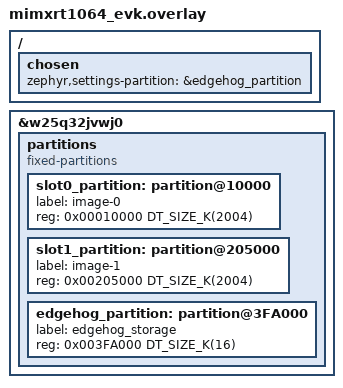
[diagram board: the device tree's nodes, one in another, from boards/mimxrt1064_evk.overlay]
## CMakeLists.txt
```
# (C) Copyright 2024, SECO Mind Srl
#
# SPDX-License-Identifier: Apache-2.0

function(concat_if_exists FILE_PATH STRING_NAME)
    # Check if the file exists
    file(GLOB FILE_TO_ADD ${FILE_PATH})

    # If the file exists, add it to the list
    if(EXISTS ${FILE_TO_ADD})
        set(${STRING_NAME} "${${STRING_NAME}};${FILE_PATH}" PARENT_SCOPE)
    endif()
endfunction()

cmake_minimum_required(VERSION 3.20.0)

# add private configuration for common modules before declaring the zephyr project
concat_if_exists(${CMAKE_CURRENT_LIST_DIR}/private.conf EXTRA_CONF_FILE)
# add per board cmake configuration
include(${CMAKE_CURRENT_LIST_DIR}/boards/${BOARD}.cmake OPTIONAL)

find_package(Zephyr REQUIRED HINTS $ENV{ZEPHYR_BASE})
project(simple)

FILE(GLOB app_sources src/*.c)

if(NOT CONFIG_WIFI)
    LIST(REMOVE_ITEM app_sources ${CMAKE_CURRENT_LIST_DIR}/src/wifi.c)
endif()

# Verify that this sample is built through sysbuild to ensure MCUboot is
# automatically included and that sample specific MCUboot configurations are
# used when building MCUboot.
test_sysbuild()

target_include_directories(app PRIVATE src/include)
target_sources(app PRIVATE ${app_sources})
```

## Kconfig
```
# (C) Copyright 2024, SECO Mind Srl
#
# SPDX-License-Identifier: Apache-2.0
#
# This file is the application Kconfig entry point. All application Kconfig
# options can be defined here or included via other application Kconfig files.
# You can browse these options using the west targets menuconfig (terminal) or
# guiconfig (GUI).

menu "Zephyr"
source "Kconfig.zephyr"
endmenu

rsource "../../Kconfig"

menu "Sample application"
    config CREDENTIAL_SECRET
        string "Astarte credential secret"
        default ""
        help
            The credential secret to be used to connect to Astarte.
            
config WIFI_SSID
    string "WiFi SSID"
    default "myssid"
    help
        SSID (network name) for the example to connect to.

config WIFI_PASSWORD
    string "WiFi Password"
    default "mypassword"
    help
        WiFi password (WPA or WPA2) for the example to use.
endmenu

module = APP
module-str = APP
source "subsys/logging/Kconfig.template.log_config"
```

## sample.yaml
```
# (C) Copyright 2024, SECO Mind Srl
#
# SPDX-License-Identifier: Apache-2.0
# This file is provided so that the application can be compiled using Twister,
# the Zephyr testing tool. In this file, multiple combinations can be specified,
# so that you can easily test all of them locally or in CI.
sample:
  description: Simple sample for using the library
  name: simple-sample
tests:
  simple.default:
    build_only: true
    integration_platforms:
      - mimxrt1064_evk
      - native_sim
```

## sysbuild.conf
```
# (C) Copyright 2024, SECO Mind Srl
#
# SPDX-License-Identifier: Apache-2.0

SB_CONFIG_BOOTLOADER_MCUBOOT=y
```

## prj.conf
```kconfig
# (C) Copyright 2024, SECO Mind Srl
#
# SPDX-License-Identifier: Apache-2.0
#
# This is a Kconfig fragment which can be used to enable debug-related options
# in the application. See the README for more details.

# logging
CONFIG_LOG=y
CONFIG_CBPRINTF_FP_SUPPORT=y

# compiler
CONFIG_DEBUG_OPTIMIZATIONS=y

# console
CONFIG_CONSOLE=y

# UART console
CONFIG_SERIAL=y
CONFIG_UART_CONSOLE=y

# Increased stack size
CONFIG_MAIN_STACK_SIZE=65536

# MQTT options
CONFIG_MQTT_KEEPALIVE=60

# DNS resolver
CONFIG_DNS_RESOLVER=y
CONFIG_DNS_RESOLVER_AI_MAX_ENTRIES=4
CONFIG_DNS_SERVER_IP_ADDRESSES=y
CONFIG_DNS_SERVER1="8.8.8.8" # Google DNS

# MbedTLS
CONFIG_MBEDTLS=y
CONFIG_MBEDTLS_BUILTIN=y
CONFIG_MBEDTLS_ENABLE_HEAP=y
# 55kB is the max absolute value, could be set much lower
CONFIG_MBEDTLS_HEAP_SIZE=55000
# 16384 is the max absolute value, could be set much lower
CONFIG_MBEDTLS_SSL_MAX_CONTENT_LEN=16384
CONFIG_MBEDTLS_PEM_CERTIFICATE_FORMAT=y # Does not include writing
CONFIG_MBEDTLS_PK_WRITE_C=y # Required for PEM writing (also needs MBEDTLS_PEM_WRITE_C)
CONFIG_MBEDTLS_ENTROPY_ENABLED=y
CONFIG_MBEDTLS_ZEPHYR_ENTROPY=y
CONFIG_MBEDTLS_USER_CONFIG_ENABLE=y
CONFIG_MBEDTLS_USER_CONFIG_FILE="../../astarte-device-sdk-zephyr/samples/common/include/tls-conf.h"
CONFIG_MBEDTLS_TLS_VERSION_1_2=y
CONFIG_MBEDTLS_CIPHER=y
CONFIG_MBEDTLS_CIPHER_ALL_ENABLED=y
CONFIG_MBEDTLS_SERVER_NAME_INDICATION=y
CONFIG_MBEDTLS_KEY_EXCHANGE_ALL_ENABLED=y
CONFIG_MBEDTLS_HASH_ALL_ENABLED=y
CONFIG_MBEDTLS_CTR_DRBG_ENABLED=y
CONFIG_MBEDTLS_HMAC_DRBG_ENABLED=y
CONFIG_MBEDTLS_CHACHAPOLY_AEAD_ENABLED=y
CONFIG_MBEDTLS_ECDH_C=y
CONFIG_MBEDTLS_ECDSA_C=y
CONFIG_MBEDTLS_ECJPAKE_C=y
CONFIG_MBEDTLS_ECP_C=y
CONFIG_MBEDTLS_ECP_ALL_ENABLED=y
CONFIG_MBEDTLS_GENPRIME_ENABLED=y
CONFIG_MBEDTLS_PKCS5_C=y
CONFIG_MBEDTLS_X509_CRL_PARSE_C=y
CONFIG_MBEDTLS_X509_CSR_PARSE_C=y
CONFIG_MBEDTLS_X509_CSR_WRITE_C=y

# Enable entropy generator
CONFIG_ENTROPY_GENERATOR=y

# Enable Network management info
CONFIG_NET_MGMT_EVENT_INFO=y

# Sockets
CONFIG_NET_SOCKETS=y
CONFIG_NET_SOCKETS_POLL_MAX=4
CONFIG_NET_SOCKETS_SOCKOPT_TLS=y

# Use DHCP for IPv4 and IPv6
CONFIG_NET_DHCPV4=y
CONFIG_NET_DHCPV6=y

# Generic networking options
CONFIG_NET_TX_STACK_SIZE=2048
CONFIG_NET_RX_STACK_SIZE=2048
CONFIG_NET_PKT_RX_COUNT=10
CONFIG_NET_PKT_TX_COUNT=10
CONFIG_NET_BUF_RX_COUNT=40
CONFIG_NET_BUF_TX_COUNT=40
CONFIG_NET_MAX_CONTEXTS=10
CONFIG_NET_MGMT=y
CONFIG_NET_MGMT_EVENT=y
CONFIG_NET_IPV4=y
CONFIG_NET_IPV6=y
CONFIG_NET_TCP=y

# Astarte device SDK
CONFIG_ASTARTE_DEVICE_SDK=y
CONFIG_ASTARTE_DEVICE_SDK_HOSTNAME="."
# The two certificate tags are the same as the root CA is the same for Astarte API and MQTT broker.
CONFIG_ASTARTE_DEVICE_SDK_HTTPS_CA_CERT_TAG=1
CONFIG_ASTARTE_DEVICE_SDK_MQTTS_CA_CERT_TAG=1
CONFIG_ASTARTE_DEVICE_SDK_CLIENT_CERT_TAG=2
CONFIG_ASTARTE_DEVICE_SDK_PAIRING_JWT=""
CONFIG_ASTARTE_DEVICE_SDK_REALM_NAME="."
CONFIG_ASTARTE_DEVICE_SDK_PERMANENT_STORAGE=n

# Configure the name of the binary
# This will also be used to identify the edgehog image
CONFIG_KERNEL_BIN_NAME="simple-sample"

# Edgehog device
CONFIG_EDGEHOG_DEVICE=y
CONFIG_EDGEHOG_DEVICE_CA_CERT_OTA_TAG=3

# System info interface data
CONFIG_EDGEHOG_DEVICE_PART_NUMBER=""
CONFIG_EDGEHOG_DEVICE_SERIAL_NUMBER=""

# WiFi credentials
CONFIG_WIFI_SSID="."
CONFIG_WIFI_PASSWORD="."

# Sample configuration
CONFIG_CREDENTIAL_SECRET="."
CONFIG_DEVICE_ID="......................"

CONFIG_NET_SOCKETS_TLS_MAX_CONTEXTS=4

# EDGEHOG_DEVICE_ZBUS_OTA_EVENT
# Enabling these options if you have enabled the EDGEHOG_DEVICE_ZBUS_OTA_EVENT.
# CONFIG_MAIN_THREAD_PRIORITY=5
# CONFIG_ZBUS_LOG_LEVEL_INF=y

CONFIG_THREAD_MONITOR=y
CONFIG_INIT_STACKS=y
CONFIG_THREAD_STACK_INFO=y

CONFIG_POSIX_TIMERS=y
CONFIG_SNTP=y
CONFIG_POSIX_CLOCK=y # deprecated but needed for the config below
CONFIG_NET_CONFIG_CLOCK_SNTP_INIT=y
CONFIG_NET_CONFIG_SNTP_INIT_SERVER="0.pool.ntp.org"
CONFIG_NET_CONFIG_SNTP_INIT_TIMEOUT=3000

CONFIG_SETTINGS=y

# Enable base64 encoding and decoding
CONFIG_BASE64=y

# Enable system hashmaps
CONFIG_SYS_HASH_MAP=y
CONFIG_SYS_HASH_FUNC32=y

# Enable JSON library
CONFIG_JSON_LIBRARY=y

# Enable networking
CONFIG_NETWORKING=y

# Enable HTTP client
CONFIG_HTTP_CLIENT=y

# MQTT options
CONFIG_MQTT_LIB=y
CONFIG_MQTT_LIB_TLS=y
CONFIG_MQTT_CLEAN_SESSION=y
CONFIG_MQTT_KEEPALIVE=60

# Enable flash
CONFIG_FLASH=y
CONFIG_FLASH_MAP=y
CONFIG_FLASH_PAGE_LAYOUT=y

# Enable NVS
CONFIG_NVS=y
# CONFIG_NVS_LOG_LEVEL_WRN=y

# Edgehog depends on
CONFIG_IMG_MANAGER=y
CONFIG_STREAM_FLASH=y
CONFIG_REBOOT=y

# CONFIG_ZVFS_OPEN_MAX=16
```

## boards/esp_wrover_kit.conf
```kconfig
# (C) Copyright 2024, SECO Mind Srl
#
# SPDX-License-Identifier: Apache-2.0

# Enable wifi drivers
CONFIG_WIFI=y
CONFIG_WIFI_ESP32=y

# Added to prevent error with missing #include <ethernet/eth_stats.h> for esp_wifi_drv.c
# Adding this line will cause CMAKE Warning: No SOURCES given to Zephyr library: drivers__ethernet
# Just ignore.
CONFIG_NET_L2_ETHERNET=y

CONFIG_NET_CONFIG_SETTINGS=y

# Enable ESP32 External RAM
CONFIG_ESP_SPIRAM=y
CONFIG_ESP32_WIFI_NET_ALLOC_SPIRAM=y
CONFIG_MBEDTLS_ENABLE_HEAP=n

# EDGEHOG_DEVICE_ZBUS_OTA_EVENT 
# Enabling these options if you have enabled the EDGEHOG_DEVICE_ZBUS_OTA_EVENT.
# CONFIG_LOG_MODE_MINIMAL=y
```

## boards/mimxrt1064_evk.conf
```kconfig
# (C) Copyright 2024, SECO Mind Srl
#
# SPDX-License-Identifier: Apache-2.0

# Ethernet settings
CONFIG_NET_L2_ETHERNET=y
CONFIG_NET_L2_ETHERNET_MGMT=y

CONFIG_EDGEHOG_DEVICE_USE_EDGEHOG_PARTITION=y
CONFIG_ETH_MCUX_RX_BUFFERS=10

CONFIG_MBEDTLS_ENABLE_HEAP=n
CONFIG_LOG_MODE_DEFERRED=y
CONFIG_LOG_BUFFER_SIZE=32768
```

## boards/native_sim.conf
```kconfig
# (C) Copyright 2024, SECO Mind Srl
#
# SPDX-License-Identifier: Apache-2.0

CONFIG_PICOLIBC_USE_MODULE=y
CONFIG_PICOLIBC=y
```

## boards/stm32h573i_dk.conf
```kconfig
# (C) Copyright 2024, SECO Mind Srl
#
# SPDX-License-Identifier: Apache-2.0

# Use a small log buffer size
CONFIG_LOG_BUFFER_SIZE=8192
```

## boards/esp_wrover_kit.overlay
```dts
/*
 * (C) Copyright 2024, SECO Mind Srl
 *
 * SPDX-License-Identifier: Apache-2.0
 */

&wifi {
	status = "okay";
};

/ {
     aliases {
             edgehog-led = &blue_led;
     };
};
```

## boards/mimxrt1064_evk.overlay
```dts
/*
 * (C) Copyright 2024, SECO Mind Srl
 *
 * SPDX-License-Identifier: Apache-2.0
 */

/delete-node/ &slot0_partition;
/delete-node/ &slot1_partition;

&w25q32jvwj0 {

	partitions {
		compatible = "fixed-partitions";
		#address-cells = <1>;
		#size-cells = <1>;

		slot0_partition: partition@10000 {
			label = "image-0";
			reg = <0x00010000 DT_SIZE_K(2004)>;
		};
		slot1_partition: partition@205000 {
			label = "image-1";
			reg = <0x00205000 DT_SIZE_K(2004)>;
		};

		/*
		* Reserve the final 16 KiB for edgehog partition
		*/
		edgehog_partition: partition@3FA000 {
			label = "edgehog_storage";
			reg = <0x003FA000 DT_SIZE_K(16)>;
		};

	};
};


/ {
	chosen {
			zephyr,settings-partition = &edgehog_partition;
	};
};
```

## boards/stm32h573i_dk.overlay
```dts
/*
 * (C) Copyright 2024, SECO Mind Srl
 *
 * SPDX-License-Identifier: Apache-2.0
 */

/delete-node/ &slot0_partition;
/delete-node/ &slot1_partition;
/delete-node/ &storage_partition;
/delete-node/ &scratch_partition;

&flash0 {
	partitions {
        compatible = "fixed-partitions";
		#address-cells = <1>;
		#size-cells = <1>;

        slot0_partition: partition@10000 {
			label = "image-0";
			reg = <0x00010000 DT_SIZE_K(792)>;
		};

		slot1_partition: partition@D6000 {
			label = "image-1";
			reg = <0x00D6000 DT_SIZE_K(792)>;
		};

		astarte_partition: partition@19C000 {
			label = "astarte";
			reg = <0x0019C000 DT_SIZE_K(128)>;
		};

        edgehog_partition: partition@1BC000 {
			label = "edgehog_storage";
			reg = <0x001BC000 DT_SIZE_K(16)>;
		};

        storage_partition: partition@1C0000 {
			label = "storage";
			reg = <0x001C0000 DT_SIZE_M(256)>;
		};
	};
};
```

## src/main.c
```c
/*
 * (C) Copyright 2024, SECO Mind Srl
 *
 * SPDX-License-Identifier: Apache-2.0
 */

#include <zephyr/kernel.h>
#include <zephyr/net/net_mgmt.h>

#if !defined(CONFIG_ASTARTE_DEVICE_SDK_DEVELOP_DISABLE_OR_IGNORE_TLS)
#include "ca_certificates.h"
#include <zephyr/net/tls_credentials.h>
#endif

#include <zephyr/logging/log.h>
LOG_MODULE_REGISTER(simple_main); // NOLINT

#include <zephyr/net/sntp.h>
#include <zephyr/posix/time.h>

#include <astarte_device_sdk/device.h>
#include <edgehog_device/device.h>
#include <edgehog_device/telemetry.h>
#include <edgehog_device/wifi_scan.h>

#ifdef CONFIG_EDGEHOG_DEVICE_ZBUS_OTA_EVENT
#include <edgehog_device/ota_event.h>
#endif

#if defined(CONFIG_WIFI)
#include "wifi.h"
#else
#include "eth.h"
#endif

/************************************************
 * Constants and defines
 ***********************************************/

#define POLL_PERIOD_MS 100
#define TELEMETRY_PERIOD_S 5

#define HTTP_TIMEOUT_MS (3 * MSEC_PER_SEC)
#define MQTT_FIRST_POLL_TIMEOUT_MS (3 * MSEC_PER_SEC)
#define MQTT_POLL_TIMEOUT_MS 200

#define DEVICE_OPERATIONAL_TIME_MS (15 * SEC_PER_MIN * MSEC_PER_SEC)

#define EDGEHOG_STACK_SIZE 8196

#define EDGEHOG_DEVICE_THREAD_FLAGS_TERMINATION 1U

// NOLINTBEGIN(cppcoreguidelines-avoid-non-const-global-variables)
K_THREAD_STACK_DEFINE(edgehog_thread_stack, EDGEHOG_STACK_SIZE);
static struct k_thread edgehog_thread_data;
static atomic_t edgehog_device_thread_flags;

/** Since the wifi_scan request does not provide a way to pass a user_data,
 * astarte_device_handle was defined as a static reference to pass it to
 * `NET_MGMT_REGISTER_EVENT_HANDLER`.
 */
static astarte_device_handle_t astarte_device_handle;
// NOLINTEND(cppcoreguidelines-avoid-non-const-global-variables)

#if defined(CONFIG_WIFI)
NET_MGMT_REGISTER_EVENT_HANDLER(wifi_scan_events, EDGEHOG_WIFI_SCAN_EVENTS_SET,
    edgehog_wifi_scan_event_handler, &astarte_device_handle);
#endif

/************************************************
 * Static functions declaration
 ***********************************************/

/**
 * @brief Handler for astarte connection events.
 *
 * @param event Astarte device connection event pointer.
 */
static void astarte_connection_events_handler(astarte_device_connection_event_t event);
/**
 * @brief Handler for astarte disconnection events.
 *
 * @param event Astarte device disconnection event pointer.
 */
static void astarte_disconnection_events_handler(astarte_device_disconnection_event_t event);

/**
 * @brief Entry point for the Edgehog device thread.
 *
 * @param device_handle Handle to the Edgehog device.
 * @param unused1 Unused parameter.
 * @param unused2 Unused parameter.
 */
static void edgehog_thread_entry_point(void *device_handle, void *unused1, void *unused2);

/**
 * @brief Handler for astarte datastream object event.
 *
 * @param event Astarte device datastream object event pointer.
 */
static void datastream_object_events_handler(astarte_device_datastream_object_event_t event);

/**
 * @brief Handler for astarte datastream individual event.
 *
 * @param event Astarte device datastream individual event pointer.
 */
static void datastream_individual_events_handler(
    astarte_device_datastream_individual_event_t event);

/**
 * @brief Handler for astarte set property event.
 *
 * @param event Astarte device data event pointer.
 */
static void properties_set_events_handler(astarte_device_property_set_event_t event);
/**
 * @brief Handler for astarte unset property event.
 *
 * @param event Astarte device data event pointer.
 */
static void properties_unset_events_handler(astarte_device_data_event_t event);

/**
 * @brief Initialize System Time
 */
static void system_time_init();

// NOLINTNEXTLINE(hicpp-function-size)
int main(void)
{
    astarte_result_t astarte_result = ASTARTE_RESULT_OK;

    LOG_INF("Edgehog example! %s\n", CONFIG_BOARD); // NOLINT

#if defined(CONFIG_WIFI)
    LOG_INF("Initializing WiFi driver."); // NOLINT
    wifi_init();
    k_sleep(K_SECONDS(5)); // sleep for 5 seconds
#else
    LOG_INF("Initializing Ethernet driver."); // NOLINT
    if (eth_connect() != 0) {
        LOG_ERR("Connectivity intialization failed!"); // NOLINT
        return -1;
    }
#endif

    system_time_init();

#if !defined(CONFIG_ASTARTE_DEVICE_SDK_DEVELOP_DISABLE_OR_IGNORE_TLS)
    tls_credential_add(CONFIG_ASTARTE_DEVICE_SDK_HTTPS_CA_CERT_TAG, TLS_CREDENTIAL_CA_CERTIFICATE,
        ca_certificate_root, sizeof(ca_certificate_root));
#endif

#if !defined(CONFIG_EDGEHOG_DEVICE_DEVELOP_DISABLE_OR_IGNORE_TLS)
    tls_credential_add(CONFIG_EDGEHOG_DEVICE_CA_CERT_OTA_TAG, TLS_CREDENTIAL_CA_CERTIFICATE,
        ota_ca_certificate_root, sizeof(ota_ca_certificate_root));
#endif

    char cred_secr[ASTARTE_PAIRING_CRED_SECR_LEN + 1] = CONFIG_CREDENTIAL_SECRET;
    char device_id[ASTARTE_DEVICE_ID_LEN + 1] = CONFIG_DEVICE_ID;

    edgehog_device_handle_t edgehog_device = NULL;

    astarte_device_config_t astarte_device_config = { 0 };
    memset(&astarte_device_config, 0, sizeof(astarte_device_config));
    astarte_device_config.http_timeout_ms = HTTP_TIMEOUT_MS;
    astarte_device_config.mqtt_connection_timeout_ms = MQTT_FIRST_POLL_TIMEOUT_MS;
    astarte_device_config.mqtt_poll_timeout_ms = MQTT_POLL_TIMEOUT_MS;
    astarte_device_config.connection_cbk = astarte_connection_events_handler;
    astarte_device_config.disconnection_cbk = astarte_disconnection_events_handler;
    astarte_device_config.datastream_object_cbk = datastream_object_events_handler;
    astarte_device_config.datastream_individual_cbk = datastream_individual_events_handler;
    astarte_device_config.property_set_cbk = properties_set_events_handler;
    astarte_device_config.property_unset_cbk = properties_unset_events_handler;
    astarte_device_config.cbk_user_data = (void *) &edgehog_device;

    memcpy(astarte_device_config.cred_secr, cred_secr, sizeof(cred_secr));
    memcpy(astarte_device_config.device_id, device_id, sizeof(device_id));

    astarte_result = astarte_device_new(&astarte_device_config, &astarte_device_handle);
    if (astarte_result != ASTARTE_RESULT_OK) {
        return -1;
    }

    edgehog_device_telemetry_config_t telemetry_config = {
        .type = EDGEHOG_TELEMETRY_SYSTEM_STATUS,
        .period_seconds = TELEMETRY_PERIOD_S,
    };

    edgehog_device_config_t edgehog_conf = {
        .astarte_device = astarte_device_handle,
        .telemetry_config = &telemetry_config,
        .telemetry_config_len = 1,
    };

    edgehog_result_t edgehog_result = edgehog_device_new(&edgehog_conf, &edgehog_device);

    if (edgehog_result != EDGEHOG_RESULT_OK) {
        LOG_ERR("Unable to create edgehog device handle"); // NOLINT
        return -1;
    }

    LOG_INF("Edgehog device created"); // NOLINT

    astarte_result = astarte_device_connect(astarte_device_handle);
    if (astarte_result != ASTARTE_RESULT_OK) {
        return -1;
    }

    while (astarte_result == ASTARTE_RESULT_OK || astarte_result == ASTARTE_RESULT_TIMEOUT) {
        k_timepoint_t timepoint = sys_timepoint_calc(K_MSEC(POLL_PERIOD_MS));

        astarte_result = astarte_device_poll(astarte_device_handle);
#ifndef CONFIG_WIFI
        eth_poll();
#endif

        k_sleep(sys_timepoint_timeout(timepoint));
    }

    LOG_ERR("Astarte device poll failure. %d -> %s", astarte_result, // NOLINT
        astarte_result_to_name(astarte_result)); // NOLINT

    LOG_INF("End of sample operation, disconnection imminent."); // NOLINT

    edgehog_device_destroy(edgehog_device);

    astarte_result = astarte_device_destroy(astarte_device_handle);
    if (astarte_result != ASTARTE_RESULT_OK) {
        LOG_ERR("Failed destroying the device."); // NOLINT
        return -1;
    }

    return 0;
}

/************************************************
 * Static functions definitions
 ***********************************************/

static void edgehog_thread_entry_point(void *device_handle, void *unused1, void *unused2)
{
    (void) unused1;
    (void) unused2;

    edgehog_device_handle_t edgehog_device = (edgehog_device_handle_t) device_handle;

    edgehog_result_t edgehog_result = edgehog_device_start(edgehog_device);
    if (edgehog_result != EDGEHOG_RESULT_OK) {
        LOG_ERR("Unable to start edgehog device"); // NOLINT
    }

    while (
        !atomic_test_bit(&edgehog_device_thread_flags, EDGEHOG_DEVICE_THREAD_FLAGS_TERMINATION)) {
        k_sleep(K_MSEC(500)); // sleep for 500 ms
    }
}

#ifdef CONFIG_EDGEHOG_DEVICE_ZBUS_OTA_EVENT
ZBUS_CHAN_DECLARE(edgehog_ota_chan);
ZBUS_SUBSCRIBER_DEFINE(ota_evt_subscriber, 4);
static void ota_subscriber_task(void *sub_ref)
{
    const struct zbus_channel *chan;

    while (!zbus_sub_wait(&ota_evt_subscriber, &chan, K_FOREVER)) {
        edgehog_ota_chan_event_t ota = { 0 };
        if (&edgehog_ota_chan == chan) {
            // Indirect message access
            zbus_chan_read(chan, &ota, K_NO_WAIT);
            switch (ota.event) {
                case EDGEHOG_OTA_INIT_EVENT:
                    LOG_DBG("From subscriber -> EDGEHOG_OTA_INIT_EVENT");
                    break;
                case EDGEHOG_OTA_SUCCESS_EVENT:
                    LOG_DBG("From subscriber -> EDGEHOG_OTA_SUCCESS_EVENT");
                    break;
                case EDGEHOG_OTA_FAILED_EVENT:
                    LOG_DBG("From subscriber -> EDGEHOG_OTA_FAILED_EVENT");
                    break;
                default:
                    LOG_DBG("From subscriber -> EDGEHOG_OTA_INIT_EVENT");
            }
        }
    }
}
K_THREAD_DEFINE(ota_subscriber_task_id, 1024, ota_subscriber_task, NULL, NULL, NULL, 3, 0, 0);
ZBUS_CHAN_ADD_OBS(edgehog_ota_chan, ota_evt_subscriber, 3);
#endif

static void astarte_connection_events_handler(astarte_device_connection_event_t event)
{
    (void) event;
    LOG_INF("Astarte device connected, session_present."); // NOLINT

    if (!atomic_test_and_set_bit(
            &edgehog_device_thread_flags, EDGEHOG_DEVICE_THREAD_FLAGS_TERMINATION)) {
        edgehog_device_handle_t *edgehog_device = (edgehog_device_handle_t *) event.user_data;

        k_thread_create(&edgehog_thread_data, edgehog_thread_stack, EDGEHOG_STACK_SIZE,
            edgehog_thread_entry_point, *edgehog_device, NULL, NULL, 0,
            K_HIGHEST_APPLICATION_THREAD_PRIO, K_NO_WAIT);
    }
}

static void datastream_object_events_handler(astarte_device_datastream_object_event_t event)
{
    edgehog_device_handle_t *edgehog_device
        = (edgehog_device_handle_t *) event.data_event.user_data;

    edgehog_device_datastream_object_events_handler(*edgehog_device, event);
}

static void datastream_individual_events_handler(astarte_device_datastream_individual_event_t event)
{
    edgehog_device_handle_t *edgehog_device
        = (edgehog_device_handle_t *) event.data_event.user_data;

    edgehog_device_datastream_individual_events_handler(*edgehog_device, event);
}

static void properties_set_events_handler(astarte_device_property_set_event_t event)
{

    edgehog_device_handle_t *edgehog_device
        = (edgehog_device_handle_t *) event.data_event.user_data;

    edgehog_device_property_set_events_handler(*edgehog_device, event);
}

static void properties_unset_events_handler(astarte_device_data_event_t event)
{
    edgehog_device_handle_t *edgehog_device = (edgehog_device_handle_t *) event.user_data;

    edgehog_device_property_unset_events_handler(*edgehog_device, event);
}

static void astarte_disconnection_events_handler(astarte_device_disconnection_event_t event)
{
    (void) event;
    LOG_INF("Astarte device disconnected"); // NOLINT
}

static void system_time_init()
{
#ifdef CONFIG_SNTP
    int ret = 0;
    struct sntp_time now;
    struct timespec tspec;

    ret = sntp_simple(
        CONFIG_NET_CONFIG_SNTP_INIT_SERVER, CONFIG_NET_CONFIG_SNTP_INIT_TIMEOUT, &now);
    if (ret == 0) {
        tspec.tv_sec = (time_t) now.seconds;
        // NOLINTBEGIN(bugprone-narrowing-conversions, hicpp-signed-bitwise,
        // readability-magic-numbers)
        tspec.tv_nsec = ((uint64_t) now.fraction * (1000lu * 1000lu * 1000lu)) >> 32;
        // NOLINTEND(bugprone-narrowing-conversions, hicpp-signed-bitwise,
        // readability-magic-numbers)
        clock_settime(CLOCK_REALTIME, &tspec);
    }
#endif
}
```

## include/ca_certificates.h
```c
/*
 * (C) Copyright 2024, SECO Mind Srl
 *
 * SPDX-License-Identifier: Apache-2.0
 */

#ifndef CA_CERTIFICATES_H
#define CA_CERTIFICATES_H

/* By default only certificates in DER format are supported. If you want to use
 * certificate in PEM format, you can enable support for it in Kconfig.
 */

static const unsigned char ca_certificate_root[]
    = { "-----BEGIN CERTIFICATE-----\n"
        "MIIDxTCCAq2gAwIBAgIBADANBgkqhkiG9w0BAQsFADCBgzELMAkGA1UEBhMCVVMx\n"
        "EDAOBgNVBAgTB0FyaXpvbmExEzARBgNVBAcTClNjb3R0c2RhbGUxGjAYBgNVBAoT\n"
        "EUdvRGFkZHkuY29tLCBJbmMuMTEwLwYDVQQDEyhHbyBEYWRkeSBSb290IENlcnRp\n"
        "ZmljYXRlIEF1dGhvcml0eSAtIEcyMB4XDTA5MDkwMTAwMDAwMFoXDTM3MTIzMTIz\n"
        "NTk1OVowgYMxCzAJBgNVBAYTAlVTMRAwDgYDVQQIEwdBcml6b25hMRMwEQYDVQQH\n"
        "EwpTY290dHNkYWxlMRowGAYDVQQKExFHb0RhZGR5LmNvbSwgSW5jLjExMC8GA1UE\n"
        "AxMoR28gRGFkZHkgUm9vdCBDZXJ0aWZpY2F0ZSBBdXRob3JpdHkgLSBHMjCCASIw\n"
        "DQYJKoZIhvcNAQEBBQADggEPADCCAQoCggEBAL9xYgjx+lk09xvJGKP3gElY6SKD\n"
        "E6bFIEMBO4Tx5oVJnyfq9oQbTqC023CYxzIBsQU+B07u9PpPL1kwIuerGVZr4oAH\n"
        "/PMWdYA5UXvl+TW2dE6pjYIT5LY/qQOD+qK+ihVqf94Lw7YZFAXK6sOoBJQ7Rnwy\n"
        "DfMAZiLIjWltNowRGLfTshxgtDj6AozO091GB94KPutdfMh8+7ArU6SSYmlRJQVh\n"
        "GkSBjCypQ5Yj36w6gZoOKcUcqeldHraenjAKOc7xiID7S13MMuyFYkMlNAJWJwGR\n"
        "tDtwKj9useiciAF9n9T521NtYJ2/LOdYq7hfRvzOxBsDPAnrSTFcaUaz4EcCAwEA\n"
        "AaNCMEAwDwYDVR0TAQH/BAUwAwEB/zAOBgNVHQ8BAf8EBAMCAQYwHQYDVR0OBBYE\n"
        "FDqahQcQZyi27/a9BUFuIMGU2g/eMA0GCSqGSIb3DQEBCwUAA4IBAQCZ21151fmX\n"
        "WWcDYfF+OwYxdS2hII5PZYe096acvNjpL9DbWu7PdIxztDhC2gV7+AJ1uP2lsdeu\n"
        "9tfeE8tTEH6KRtGX+rcuKxGrkLAngPnon1rpN5+r5N9ss4UXnT3ZJE95kTXWXwTr\n"
        "gIOrmgIttRD02JDHBHNA7XIloKmf7J6raBKZV8aPEjoJpL1E/QYVN8Gb5DKj7Tjo\n"
        "2GTzLH4U/ALqn83/B2gX2yKQOC16jdFU8WnjXzPKej17CuPKf1855eJ1usV2GDPO\n"
        "LPAvTK33sefOT6jEm0pUBsV/fdUID+Ic/n4XuKxe9tQWskMJDE32p2u0mYRlynqI\n"
        "4uJEvlz36hz1\n"
        "-----END CERTIFICATE-----\n" };

#endif /* CA_CERTIFICATES_H */
```

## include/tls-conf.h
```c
/*
 * (C) Copyright 2024, SECO Mind Srl
 *
 * SPDX-License-Identifier: Apache-2.0
 */

#ifndef TLS_CONF_H
#define TLS_CONF_H

/**
 * \def MBEDTLS_PEM_PARSE_C
 *
 * Enable PEM decoding / parsing.
 *
 * Module:  library/pem.c
 * Caller:  library/dhm.c
 *          library/pkparse.c
 *          library/x509_crl.c
 *          library/x509_crt.c
 *          library/x509_csr.c
 *
 * Requires: MBEDTLS_BASE64_C
 *           optionally MBEDTLS_MD5_C, or PSA Crypto with MD5 (see below)
 *
 * \warning When parsing password-protected files, if MD5 is provided only by
 * a PSA driver, you must call psa_crypto_init() before the first file.
 *
 * This modules adds support for decoding / parsing PEM files.
 */
#define MBEDTLS_PEM_PARSE_C

/**
 * \def MBEDTLS_PEM_WRITE_C
 *
 * Enable PEM encoding / writing.
 *
 * Module:  library/pem.c
 * Caller:  library/pkwrite.c
 *          library/x509write_crt.c
 *          library/x509write_csr.c
 *
 * Requires: MBEDTLS_BASE64_C
 *
 * This modules adds support for encoding / writing PEM files.
 */
#define MBEDTLS_PEM_WRITE_C

/**
 * \def MBEDTLS_X509_USE_C
 *
 * Enable X.509 core for using certificates.
 *
 * Module:  library/x509.c
 * Caller:  library/x509_crl.c
 *          library/x509_crt.c
 *          library/x509_csr.c
 *
 * Requires: MBEDTLS_ASN1_PARSE_C, MBEDTLS_BIGNUM_C, MBEDTLS_OID_C, MBEDTLS_PK_PARSE_C,
 *           (MBEDTLS_MD_C or MBEDTLS_USE_PSA_CRYPTO)
 *
 * \warning If building with MBEDTLS_USE_PSA_CRYPTO, you must call
 * psa_crypto_init() before doing any X.509 operation.
 *
 * This module is required for the X.509 parsing modules.
 */
#define MBEDTLS_X509_USE_C

/**
 * \def MBEDTLS_X509_CRT_PARSE_C
 *
 * Enable X.509 certificate parsing.
 *
 * Module:  library/x509_crt.c
 * Caller:  library/ssl_tls.c
 *          library/ssl*_client.c
 *          library/ssl*_server.c
 *
 * Requires: MBEDTLS_X509_USE_C
 *
 * This module is required for X.509 certificate parsing.
 */
#define MBEDTLS_X509_CRT_PARSE_C

/**
 * \def MBEDTLS_X509_CRL_PARSE_C
 *
 * Enable X.509 CRL parsing.
 *
 * Module:  library/x509_crl.c
 * Caller:  library/x509_crt.c
 *
 * Requires: MBEDTLS_X509_USE_C
 *
 * This module is required for X.509 CRL parsing.
 */
#define MBEDTLS_X509_CRL_PARSE_C

/**
 * \def MBEDTLS_X509_CSR_PARSE_C
 *
 * Enable X.509 Certificate Signing Request (CSR) parsing.
 *
 * Module:  library/x509_csr.c
 * Caller:  library/x509_crt_write.c
 *
 * Requires: MBEDTLS_X509_USE_C
 *
 * This module is used for reading X.509 certificate request.
 */
#define MBEDTLS_X509_CSR_PARSE_C

/**
 * \def MBEDTLS_X509_CREATE_C
 *
 * Enable X.509 core for creating certificates.
 *
 * Module:  library/x509_create.c
 *
 * Requires: MBEDTLS_BIGNUM_C, MBEDTLS_OID_C, MBEDTLS_PK_PARSE_C,
 *           (MBEDTLS_MD_C or MBEDTLS_USE_PSA_CRYPTO)
 *
 * \warning If building with MBEDTLS_USE_PSA_CRYPTO, you must call
 * psa_crypto_init() before doing any X.509 create operation.
 *
 * This module is the basis for creating X.509 certificates and CSRs.
 */
#define MBEDTLS_X509_CREATE_C

/**
 * \def MBEDTLS_X509_CRT_WRITE_C
 *
 * Enable creating X.509 certificates.
 *
 * Module:  library/x509_crt_write.c
 *
 * Requires: MBEDTLS_X509_CREATE_C
 *
 * This module is required for X.509 certificate creation.
 */
#define MBEDTLS_X509_CRT_WRITE_C

/**
 * \def MBEDTLS_X509_CSR_WRITE_C
 *
 * Enable creating X.509 Certificate Signing Requests (CSR).
 *
 * Module:  library/x509_csr_write.c
 *
 * Requires: MBEDTLS_X509_CREATE_C
 *
 * This module is required for X.509 certificate request writing.
 */
#define MBEDTLS_X509_CSR_WRITE_C

#endif /* TLS_CONF_H */
```

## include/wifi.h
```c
/*
 * (C) Copyright 2024, SECO Mind Srl
 *
 * SPDX-License-Identifier: Apache-2.0
 */

#ifndef WIFI_H
#define WIFI_H

/**
 * @brief Initialize the wifi driver
 */
void wifi_init(void);

#endif /* WIFI_H */
```

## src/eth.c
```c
/*
 * (C) Copyright 2024, SECO Mind Srl
 *
 * SPDX-License-Identifier: Apache-2.0
 */

#include "eth.h"

#include <zephyr/kernel.h>
#include <zephyr/net/ethernet.h>
#include <zephyr/net/ethernet_mgmt.h>

#include <zephyr/logging/log.h>
LOG_MODULE_REGISTER(eth, CONFIG_APP_LOG_LEVEL); // NOLINT

/************************************************
 *        Constants, statics and defines        *
 ***********************************************/

// NOLINTBEGIN(cppcoreguidelines-avoid-non-const-global-variables)
static struct net_mgmt_event_callback eth_cb;
static struct net_mgmt_event_callback status_cb;
static struct net_mgmt_event_callback ipv6_cb;
static struct net_mgmt_event_callback ipv4_cb;
static struct net_mgmt_event_callback l4_cb;

static K_SEM_DEFINE(ipv4_address_obtained, 0, 1);
// NOLINTEND(cppcoreguidelines-avoid-non-const-global-variables)

/************************************************
 *       Callbacks declaration/definition       *
 ***********************************************/

static void eth_mgmt_event_handler(
    struct net_mgmt_event_callback *event_cb, uint32_t mgmt_event, struct net_if *iface)
{
    (void) event_cb;
    (void) iface;

    // NOLINTBEGIN(hicpp-signed-bitwise)
    switch (mgmt_event) {
        case NET_EVENT_ETHERNET_CARRIER_ON:
            LOG_DBG("Ethernet event: NET_EVENT_ETHERNET_CARRIER_ON."); // NOLINT
            break;

        case NET_EVENT_ETHERNET_CARRIER_OFF:
            LOG_DBG("Ethernet event: NET_EVENT_ETHERNET_CARRIER_OFF."); // NOLINT
            break;

        case NET_EVENT_ETHERNET_VLAN_TAG_ENABLED:
            LOG_DBG("Ethernet event: NET_EVENT_ETHERNET_VLAN_TAG_ENABLED."); // NOLINT
            break;

        case NET_EVENT_ETHERNET_VLAN_TAG_DISABLED:
            LOG_DBG("Ethernet event: NET_EVENT_ETHERNET_VLAN_TAG_DISABLED."); // NOLINT
            break;

        default:
            LOG_DBG("Status network event: %d.", mgmt_event); // NOLINT
            break;
    }
    // NOLINTEND(hicpp-signed-bitwise)
}

static void status_mgmt_event_handler(
    struct net_mgmt_event_callback *event_cb, uint32_t mgmt_event, struct net_if *iface)
{
    (void) event_cb;
    (void) iface;

    // NOLINTBEGIN(hicpp-signed-bitwise)
    switch (mgmt_event) {
        case NET_EVENT_IF_DOWN:
            LOG_DBG("Network event: NET_EVENT_IF_DOWN."); // NOLINT
            break;

        case NET_EVENT_IF_UP:
            LOG_DBG("Network event: NET_EVENT_IF_UP."); // NOLINT
            break;

        case NET_EVENT_IF_ADMIN_DOWN:
            LOG_DBG("Network event: NET_EVENT_IF_ADMIN_DOWN."); // NOLINT
            break;

        case NET_EVENT_IF_ADMIN_UP:
            LOG_DBG("Network event: NET_EVENT_IF_ADMIN_UP."); // NOLINT
            break;

        default:
            LOG_DBG("Status network event: %d.", mgmt_event); // NOLINT
            break;
    }
    // NOLINTEND(hicpp-signed-bitwise)
}

static void ipv6_mgmt_event_handler(
    struct net_mgmt_event_callback *event_cb, uint32_t mgmt_event, struct net_if *iface)
{
    (void) event_cb;
    (void) iface;

    // NOLINTBEGIN(hicpp-signed-bitwise)
    switch (mgmt_event) {

        case NET_EVENT_IPV6_ADDR_ADD:
            LOG_DBG("IPv6 network event: NET_EVENT_IPV6_ADDR_ADD."); // NOLINT
            break;

        case NET_EVENT_IPV6_ADDR_DEL:
            LOG_DBG("IPv6 network event: NET_EVENT_IPV6_ADDR_DEL."); // NOLINT
            break;

        case NET_EVENT_IPV6_MADDR_ADD:
            LOG_DBG("IPv6 network event: NET_EVENT_IPV6_MADDR_ADD."); // NOLINT
            break;

        case NET_EVENT_IPV6_MADDR_DEL:
            LOG_DBG("IPv6 network event: NET_EVENT_IPV6_MADDR_DEL."); // NOLINT
            break;

        case NET_EVENT_IPV6_PREFIX_ADD:
            LOG_DBG("IPv6 network event: NET_EVENT_IPV6_PREFIX_ADD."); // NOLINT
            break;

        case NET_EVENT_IPV6_PREFIX_DEL:
            LOG_DBG("IPv6 network event: NET_EVENT_IPV6_PREFIX_DEL."); // NOLINT
            break;

        case NET_EVENT_IPV6_MCAST_JOIN:
            LOG_DBG("IPv6 network event: NET_EVENT_IPV6_MCAST_JOIN."); // NOLINT
            break;

        case NET_EVENT_IPV6_MCAST_LEAVE:
            LOG_DBG("IPv6 network event: NET_EVENT_IPV6_MCAST_LEAVE."); // NOLINT
            break;

        case NET_EVENT_IPV6_ROUTER_ADD:
            LOG_DBG("IPv6 network event: NET_EVENT_IPV6_ROUTER_ADD."); // NOLINT
            break;

        case NET_EVENT_IPV6_ROUTER_DEL:
            LOG_DBG("IPv6 network event: NET_EVENT_IPV6_ROUTER_DEL."); // NOLINT
            break;

        case NET_EVENT_IPV6_ROUTE_ADD:
            LOG_DBG("IPv6 network event: NET_EVENT_IPV6_ROUTE_ADD."); // NOLINT
            break;

        case NET_EVENT_IPV6_ROUTE_DEL:
            LOG_DBG("IPv6 network event: NET_EVENT_IPV6_ROUTE_DEL."); // NOLINT
            break;

        case NET_EVENT_IPV6_DAD_SUCCEED:
            LOG_DBG("IPv6 network event: NET_EVENT_IPV6_DAD_SUCCEED."); // NOLINT
            break;

        case NET_EVENT_IPV6_DAD_FAILED:
            LOG_DBG("IPv6 network event: NET_EVENT_IPV6_DAD_FAILED."); // NOLINT
            break;

        case NET_EVENT_IPV6_NBR_ADD:
            LOG_DBG("IPv6 network event: NET_EVENT_IPV6_NBR_ADD."); // NOLINT
            break;

        case NET_EVENT_IPV6_NBR_DEL:
            LOG_DBG("IPv6 network event: NET_EVENT_IPV6_NBR_DEL."); // NOLINT
            break;

        case NET_EVENT_IPV6_DHCP_START:
            LOG_DBG("IPv6 network event: NET_EVENT_IPV6_DHCP_START."); // NOLINT
            break;

        case NET_EVENT_IPV6_DHCP_BOUND:
            LOG_DBG("IPv6 network event: NET_EVENT_IPV6_DHCP_BOUND."); // NOLINT
            break;

        case NET_EVENT_IPV6_DHCP_STOP:
            LOG_DBG("IPv6 network event: NET_EVENT_IPV6_DHCP_STOP."); // NOLINT
            break;

        default:
            LOG_DBG("IPv6 network event: %d.", mgmt_event); // NOLINT
            break;
    }
    // NOLINTEND(hicpp-signed-bitwise)
}

static void ipv4_mgmt_event_handler(
    struct net_mgmt_event_callback *event_cb, uint32_t mgmt_event, struct net_if *iface)
{
    (void) event_cb;
    (void) iface;

    // NOLINTBEGIN(hicpp-signed-bitwise)
    switch (mgmt_event) {

        case NET_EVENT_IPV4_ADDR_ADD:
            LOG_DBG("Network event: NET_EVENT_IPV4_ADDR_ADD."); // NOLINT
            k_sem_give(&ipv4_address_obtained);
            break;

        case NET_EVENT_IPV4_ADDR_DEL:
            LOG_DBG("Network event: NET_EVENT_IPV4_ADDR_DEL."); // NOLINT
            k_sem_take(&ipv4_address_obtained, K_NO_WAIT);
            break;

        case NET_EVENT_IPV4_MADDR_ADD:
            LOG_DBG("Network event: NET_EVENT_IPV4_MADDR_ADD."); // NOLINT
            break;

        case NET_EVENT_IPV4_MADDR_DEL:
            LOG_DBG("Network event: NET_EVENT_IPV4_MADDR_DEL."); // NOLINT
            break;

        case NET_EVENT_IPV4_ROUTER_ADD:
            LOG_DBG("Network event: NET_EVENT_IPV4_ROUTER_ADD."); // NOLINT
            break;

        case NET_EVENT_IPV4_ROUTER_DEL:
            LOG_DBG("Network event: NET_EVENT_IPV4_ROUTER_DEL."); // NOLINT
            break;

        case NET_EVENT_IPV4_DHCP_START:
            LOG_DBG("Network event: NET_EVENT_IPV4_DHCP_START."); // NOLINT
            break;

        case NET_EVENT_IPV4_DHCP_BOUND:
            LOG_DBG("Network event: NET_EVENT_IPV4_DHCP_BOUND."); // NOLINT
            break;

        case NET_EVENT_IPV4_DHCP_STOP:
            LOG_DBG("Network event: NET_EVENT_IPV4_DHCP_STOP."); // NOLINT
            break;

        case NET_EVENT_IPV4_MCAST_JOIN:
            LOG_DBG("Network event: NET_EVENT_IPV4_MCAST_JOIN."); // NOLINT
            break;

        case NET_EVENT_IPV4_MCAST_LEAVE:
            LOG_DBG("Network event: NET_EVENT_IPV4_MCAST_LEAVE."); // NOLINT
            break;

        default:
            LOG_DBG("Network event: %d.", mgmt_event); // NOLINT
            break;
    }
    // NOLINTEND(hicpp-signed-bitwise)
}

static void l4_mgmt_event_handler(
    struct net_mgmt_event_callback *event_cb, uint32_t mgmt_event, struct net_if *iface)
{
    (void) event_cb;
    (void) iface;

    // NOLINTBEGIN(hicpp-signed-bitwise)
    switch (mgmt_event) {

        case NET_EVENT_L4_CONNECTED:
            LOG_DBG("Network event: NET_EVENT_L4_CONNECTED."); // NOLINT
            break;

        case NET_EVENT_L4_DISCONNECTED:
            LOG_DBG("Network event: NET_EVENT_L4_DISCONNECTED."); // NOLINT
            break;

        case NET_EVENT_DNS_SERVER_ADD:
            LOG_DBG("Network event: NET_EVENT_DNS_SERVER_ADD."); // NOLINT
            break;

        case NET_EVENT_DNS_SERVER_DEL:
            LOG_DBG("Network event: NET_EVENT_DNS_SERVER_DEL."); // NOLINT
            break;

        case NET_EVENT_HOSTNAME_CHANGED:
            LOG_DBG("Network event: NET_EVENT_HOSTNAME_CHANGED."); // NOLINT
            break;

        default:
            LOG_DBG("Network event: %d.", mgmt_event); // NOLINT
            break;
    }
    // NOLINTEND(hicpp-signed-bitwise)
}

/************************************************
 * Global functions definition
 ***********************************************/

int eth_connect(void)
{
    LOG_INF("Connecting through ethernet..."); // NOLINT

    // NOLINTBEGIN(hicpp-signed-bitwise, misc-redundant-expression)
    net_mgmt_init_event_callback(&eth_cb, eth_mgmt_event_handler,
        NET_EVENT_ETHERNET_CARRIER_ON | NET_EVENT_ETHERNET_CARRIER_OFF
            | NET_EVENT_ETHERNET_VLAN_TAG_ENABLED | NET_EVENT_ETHERNET_VLAN_TAG_DISABLED);
    net_mgmt_init_event_callback(&status_cb, status_mgmt_event_handler,
        NET_EVENT_IF_DOWN | NET_EVENT_IF_UP | NET_EVENT_IF_ADMIN_DOWN | NET_EVENT_IF_ADMIN_UP);
    net_mgmt_init_event_callback(&ipv6_cb, ipv6_mgmt_event_handler,
        NET_EVENT_IPV6_ADDR_ADD | NET_EVENT_IPV6_ADDR_DEL | NET_EVENT_IPV6_MADDR_ADD
            | NET_EVENT_IPV6_MADDR_DEL | NET_EVENT_IPV6_PREFIX_ADD | NET_EVENT_IPV6_PREFIX_DEL
            | NET_EVENT_IPV6_MCAST_JOIN | NET_EVENT_IPV6_MCAST_LEAVE | NET_EVENT_IPV6_ROUTER_ADD
            | NET_EVENT_IPV6_ROUTER_DEL | NET_EVENT_IPV6_ROUTE_ADD | NET_EVENT_IPV6_ROUTE_DEL
            | NET_EVENT_IPV6_DAD_SUCCEED | NET_EVENT_IPV6_DAD_FAILED | NET_EVENT_IPV6_NBR_ADD
            | NET_EVENT_IPV6_NBR_DEL | NET_EVENT_IPV6_DHCP_START | NET_EVENT_IPV6_DHCP_BOUND
            | NET_EVENT_IPV6_DHCP_STOP);
    net_mgmt_init_event_callback(&ipv4_cb, ipv4_mgmt_event_handler,
        NET_EVENT_IPV4_ADDR_ADD | NET_EVENT_IPV4_ADDR_DEL | NET_EVENT_IPV4_MADDR_ADD
            | NET_EVENT_IPV4_MADDR_DEL | NET_EVENT_IPV4_ROUTER_ADD | NET_EVENT_IPV4_ROUTER_DEL
            | NET_EVENT_IPV4_DHCP_START | NET_EVENT_IPV4_DHCP_BOUND | NET_EVENT_IPV4_DHCP_STOP
            | NET_EVENT_IPV4_MCAST_JOIN | NET_EVENT_IPV4_MCAST_LEAVE);
    net_mgmt_init_event_callback(&l4_cb, l4_mgmt_event_handler,
        NET_EVENT_L4_CONNECTED | NET_EVENT_L4_DISCONNECTED | NET_EVENT_DNS_SERVER_ADD
            | NET_EVENT_DNS_SERVER_DEL | NET_EVENT_HOSTNAME_CHANGED);
    // NOLINTEND(hicpp-signed-bitwise, misc-redundant-expression)

    net_mgmt_add_event_callback(&eth_cb);
    net_mgmt_add_event_callback(&status_cb);
    net_mgmt_add_event_callback(&ipv6_cb);
    net_mgmt_add_event_callback(&ipv4_cb);
    net_mgmt_add_event_callback(&l4_cb);

    struct net_if *iface = net_if_get_default();
    if (!iface) {
        LOG_ERR("Default interface non existant."); // NOLINT
        return -1;
    }

    LOG_INF("Waiting for Ethernet interface to be operational."); // NOLINT
    while (net_if_oper_state(iface) != NET_IF_OPER_UP) {
        k_sleep(K_MSEC(200));
    }

    const struct device *dev = net_if_get_device(iface);
    LOG_INF("Default network interface device name: %s.", dev->name); // NOLINT
    struct ethernet_context *eth_ctx = net_if_l2_data(iface);
    LOG_INF("Ethernet carrier: %s.", eth_ctx->is_net_carrier_up ? "UP" : "DOWN"); // NOLINT
    LOG_INF("Ethernet context is initialized: %s.", eth_ctx->is_init ? "YES" : "NO"); // NOLINT
    enum net_if_oper_state iface_oper_state = net_if_oper_state(iface);
    LOG_INF("Default network interface operational state: %d.", iface_oper_state); // NOLINT

#ifdef CONFIG_NET_DHCPV4
    net_dhcpv4_start(iface);

    LOG_INF("Waiting for an IPv4 address (DHCP)."); // NOLINT
    while (k_sem_count_get(&ipv4_address_obtained) == 0) {
        k_sleep(K_MSEC(200));
    }
#endif

    k_sleep(K_MSEC(500));

    LOG_INF("Ready..."); // NOLINT

    return 0;
}

void eth_poll(void)
{
    struct net_if *iface = net_if_get_default();
    if (!iface) {
        LOG_ERR("Default interface non existant."); // NOLINT
        return;
    }

    // Check if connected
    while (net_if_oper_state(iface) != NET_IF_OPER_UP) {
        LOG_WRN("Ethernet interface is non operational."); // NOLINT
        k_sleep(K_SECONDS(1));
    }

// Restart DHCP if required.
#ifdef CONFIG_NET_DHCPV4
    if (k_sem_count_get(&ipv4_address_obtained) == 0) {
        LOG_WRN("Missing IPv4 address."); // NOLINT
        net_dhcpv4_restart(iface);
        LOG_INF("Waiting for an IPv4 address (DHCP)."); // NOLINT
        while (k_sem_count_get(&ipv4_address_obtained) == 0) {
            k_sleep(K_MSEC(200));
        }
        LOG_INF("Ready..."); // NOLINT
    }
#endif

    k_sleep(K_MSEC(500));
}
```

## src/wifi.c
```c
/*
 * (C) Copyright 2024, SECO Mind Srl
 *
 * SPDX-License-Identifier: Apache-2.0
 */

#include "wifi.h"

#include <errno.h>
#include <zephyr/kernel.h>
#include <zephyr/net/net_event.h>
#include <zephyr/net/net_if.h>
#include <zephyr/net/wifi_mgmt.h>

#include <zephyr/logging/log.h>
LOG_MODULE_REGISTER(wifi, CONFIG_APP_LOG_LEVEL); // NOLINT

static K_SEM_DEFINE(wifi_connected, 0, 1);
static K_SEM_DEFINE(ipv4_address_obtained, 0, 1);

static struct net_mgmt_event_callback wifi_cb;
static struct net_mgmt_event_callback ipv4_cb;

static void handle_wifi_connect_result(struct net_mgmt_event_callback *cb)
{
    const struct wifi_status *status = (const struct wifi_status *) cb->info;

    if (status->status) {
        LOG_ERR("Connection request failed (%d)\n", status->status);
    } else {
        LOG_INF("Connected\n");
        k_sem_give(&wifi_connected);
    }
}

static void handle_wifi_disconnect_result(struct net_mgmt_event_callback *cb)
{
    const struct wifi_status *status = (const struct wifi_status *) cb->info;

    if (status->status) {
        LOG_ERR("Disconnection request (%d)\n", status->status);
    } else {
        LOG_INF("Disconnected\n");
        k_sem_take(&wifi_connected, K_NO_WAIT);
    }
}

static void handle_ipv4_result(struct net_if *iface)
{
    int i = 0;

    for (i = 0; i < NET_IF_MAX_IPV4_ADDR; i++) {

        char buf[NET_IPV4_ADDR_LEN];

        if (iface->config.ip.ipv4->unicast[i].addr_type != NET_ADDR_DHCP) {
            continue;
        }

        LOG_INF("IPv4 address: %s\n",
            net_addr_ntop(
                AF_INET, &iface->config.ip.ipv4->unicast[i].address.in_addr, buf, sizeof(buf)));
        LOG_INF("Subnet: %s\n",
            net_addr_ntop(AF_INET, &iface->config.ip.ipv4->netmask, buf, sizeof(buf)));
        LOG_INF(
            "Router: %s\n", net_addr_ntop(AF_INET, &iface->config.ip.ipv4->gw, buf, sizeof(buf)));
    }

    k_sem_give(&ipv4_address_obtained);
}

static void wifi_mgmt_event_handler(
    struct net_mgmt_event_callback *cb, uint32_t mgmt_event, struct net_if *iface)
{
    switch (mgmt_event) {

        case NET_EVENT_WIFI_CONNECT_RESULT:
            handle_wifi_connect_result(cb);
            break;

        case NET_EVENT_WIFI_DISCONNECT_RESULT:
            handle_wifi_disconnect_result(cb);
            break;

        case NET_EVENT_IPV4_ADDR_ADD:
            handle_ipv4_result(iface);
            break;

        default:
            break;
    }
}

void wifi_connect(void)
{
    struct net_if *iface = net_if_get_default();

    struct wifi_connect_req_params wifi_params = { 0 };

    wifi_params.ssid = CONFIG_WIFI_SSID;
    wifi_params.psk = CONFIG_WIFI_PASSWORD;
    wifi_params.ssid_length = strlen(CONFIG_WIFI_SSID);
    wifi_params.psk_length = strlen(CONFIG_WIFI_PASSWORD);
    wifi_params.channel = WIFI_CHANNEL_ANY;
    wifi_params.security = WIFI_SECURITY_TYPE_PSK;
    wifi_params.band = WIFI_FREQ_BAND_2_4_GHZ;
    wifi_params.mfp = WIFI_MFP_OPTIONAL;

    LOG_INF("Connecting to SSID: %s\n", wifi_params.ssid);

    if (net_mgmt(NET_REQUEST_WIFI_CONNECT, iface, &wifi_params,
            sizeof(struct wifi_connect_req_params))) {
        LOG_INF("WiFi Connection Request Failed\n");
    }
}

void wifi_status(void)
{
    struct net_if *iface = net_if_get_default();

    struct wifi_iface_status status = { 0 };

    if (net_mgmt(NET_REQUEST_WIFI_IFACE_STATUS, iface, &status, sizeof(struct wifi_iface_status))) {
        LOG_INF("WiFi Status Request Failed\n");
    }

    LOG_INF("\n");

    if (status.state >= WIFI_STATE_ASSOCIATED) {
        LOG_INF("SSID: %-32s\n", status.ssid);
        LOG_INF("Band: %s\n", wifi_band_txt(status.band));
        LOG_INF("Channel: %d\n", status.channel);
        LOG_INF("Security: %s\n", wifi_security_txt(status.security));
        LOG_INF("RSSI: %d\n", status.rssi);
    }
}

void wifi_disconnect(void)
{
    struct net_if *iface = net_if_get_default();

    if (net_mgmt(NET_REQUEST_WIFI_DISCONNECT, iface, NULL, 0)) {
        LOG_INF("WiFi Disconnection Request Failed\n");
    }
}

void wifi_init(void)
{
    LOG_INF("Initializing wifi...\n\n");

    net_mgmt_init_event_callback(&wifi_cb, wifi_mgmt_event_handler,
        NET_EVENT_WIFI_CONNECT_RESULT | NET_EVENT_WIFI_DISCONNECT_RESULT);

    net_mgmt_init_event_callback(&ipv4_cb, wifi_mgmt_event_handler, NET_EVENT_IPV4_ADDR_ADD);

    net_mgmt_add_event_callback(&wifi_cb);
    net_mgmt_add_event_callback(&ipv4_cb);

    do {
        wifi_connect();
    } while (k_sem_take(&wifi_connected, K_SECONDS(1)) != 0);
    wifi_status();
    k_sem_take(&ipv4_address_obtained, K_FOREVER);

    LOG_INF("Ready...\n\n");
}
```
